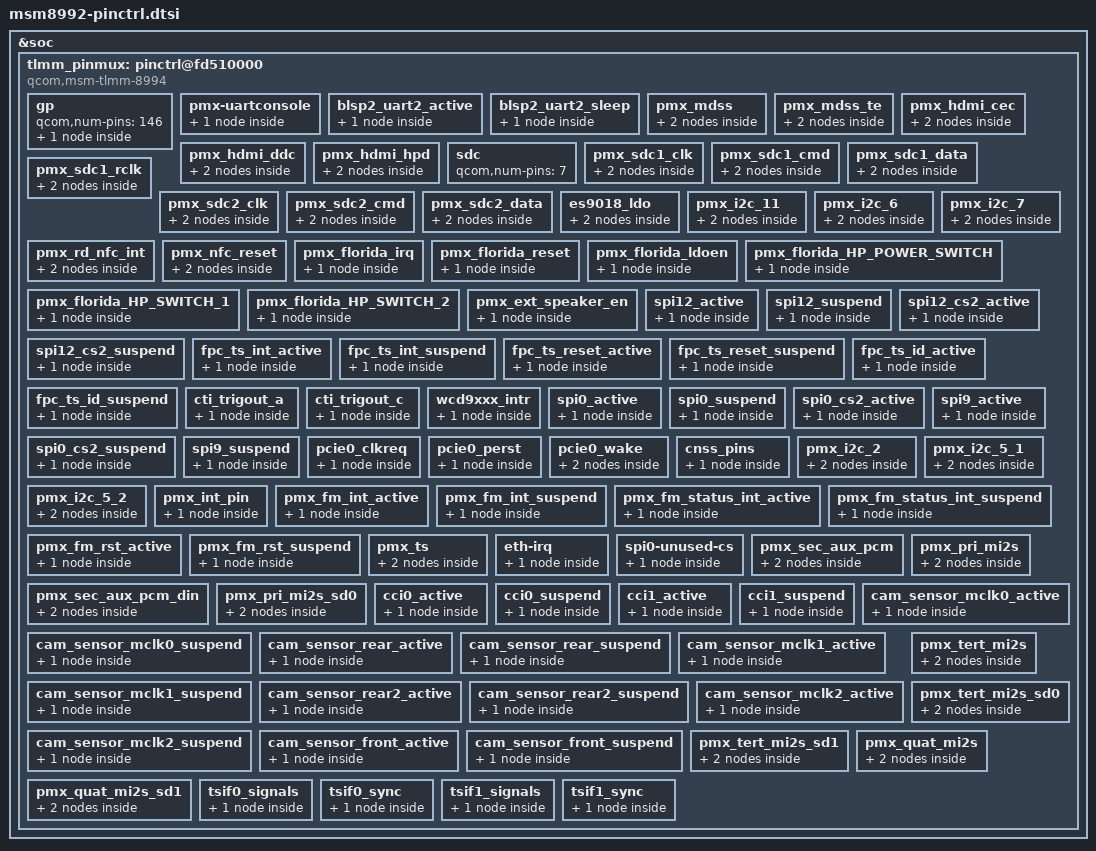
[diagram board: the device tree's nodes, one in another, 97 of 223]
/* Copyright (c) 2013-2015, The Linux Foundation. All rights reserved.
 *
 * This program is free software; you can redistribute it and/or modify
 * it under the terms of the GNU General Public License version 2 and
 * only version 2 as published by the Free Software Foundation.
 *
 * This program is distributed in the hope that it will be useful,
 * but WITHOUT ANY WARRANTY; without even the implied warranty of
 * MERCHANTABILITY or FITNESS FOR A PARTICULAR PURPOSE.  See the
 * GNU General Public License for more details.
 */

&soc {
	tlmm_pinmux: pinctrl@fd510000 {
		compatible = "qcom,msm-tlmm-8994", "qcom,msm-tlmm-8974";
		reg = <0xfd510000 0x4000>;
		interrupts = <0 208 0>;

		/*General purpose pins*/
		gp: gp {
			qcom,num-pins = <146>;
			#qcom,pin-cells = <1>;

			msm_gpio: msm_gpio {
				compatible = "qcom,msm-tlmm-gp";
				gpio-controller;
				#gpio-cells = <2>;
				interrupt-controller;
				#interrupt-cells = <2>;
				qcom,direct-connect-irqs = <8>;
				num_irqs = <146>;
			};
		};

		pmx-uartconsole {
			qcom,pins = <&gp 4>, <&gp 5>;
			qcom,num-grp-pins = <2>;
			qcom,pin-func = <2>;
			label = "uart-console";

		uart_console_sleep: uart-console {
				drive-strength = <2>;
				bias-pull-down;
			};
		};

		blsp2_uart2_active {
			qcom,pins = <&gp 45>, <&gp 46>, <&gp 47>, <&gp 48>;
			qcom,num-grp-pins = <4>;
			qcom,pin-func = <2>;
		        label = "blsp2_uart2_active";
			hsuart_active: default {
				drive-strength = <16>;
				bias-disable;
			};
		};

		blsp2_uart2_sleep {
			qcom,pins = <&gp 45>, <&gp 46>, <&gp 47>, <&gp 48>;
			qcom,num-grp-pins = <4>;
			qcom,pin-func = <0>;
		        label = "blsp2_uart2_sleep";
			hsuart_sleep: sleep {
				drive-strength = <2>;
				bias-disable;
			};
		};

		pmx_mdss: pmx_mdss {
			label = "mdss-pins";
			qcom,pin-func = <0>;
			mdss_dsi_active: active {
				drive-strength = <8>; /* 8 mA */
				bias-disable = <0>; /* no pull */
			};
			mdss_dsi_suspend: suspend {
				drive-strength = <2>; /* 2 mA */
				bias-pull-down; /* pull down */
			};
		};

		pmx_mdss_te: pmx_mdss_te {
			label = "mdss-te-pins";
			qcom,pin-func = <1>;
			mdss_te_active: active {
				drive-strength = <2>; /* 8 mA */
				bias-pull-down = <0>; /* pull down*/
				input-debounce = <0>;
			};
			mdss_te_suspend: suspend {
				drive-strength = <2>; /* 2 mA */
				bias-pull-down; /* pull down */
				input-debounce = <0>;
			};
		};

		pmx_hdmi_cec: pmx_hdmi_cec {
			qcom,pin-func = <1>;
			label = "hdmi-cec-pins";
			mdss_hdmi_cec_active: cec_active {
				drive-strength = <2>;
				bias-pull-up;
			};
			mdss_hdmi_cec_suspend: cec_suspend {
				drive-strength = <2>;
				bias-pull-down;
			};
		};

		pmx_hdmi_ddc: pmx_hdmi_ddc {
			qcom,pin-func = <1>;
			label = "hdmi-ddc-pins";
			mdss_hdmi_ddc_active: ddc_active {
				drive-strength = <2>;
				bias-pull-up;
			};
			mdss_hdmi_ddc_suspend: ddc_suspend {
				drive-strength = <2>;
				bias-pull-down;
			};
		};

		pmx_hdmi_hpd: pmx_hdmi_hpd {
			qcom,pin-func = <1>;
			label = "hdmi-hpd-pin";
			mdss_hdmi_hpd_active: hpd_active {
				drive-strength = <16>;
				bias-pull-down;
			};
			mdss_hdmi_hpd_suspend: hpd_suspend {
				drive-strength = <2>;
				bias-pull-down;
			};
		};
		/* SDC pin type */
		sdc: sdc {
			/* 0-3 for sdc1 4-6 for sdc2 */
			qcom,num-pins = <7>;
			/* Order of pins */
			/* SDC1: CLK -> 0, CMD -> 1, DATA -> 2, RCLK -> 3 */
			/* SDC2: CLK -> 4, CMD -> 5, DATA -> 6 */
			#qcom,pin-cells = <1>;
		};

		pmx_sdc1_clk {
			qcom,pins = <&sdc 0>;
			qcom,num-grp-pins = <1>;
			label = "sdc1-clk";
			sdc1_clk_on: clk_on {
				bias-disable; /* NO pull */
				drive-strength = <16>; /* 16 MA */
			};
			sdc1_clk_off: clk_off {
				bias-disable; /* NO pull */
				drive-strength = <2>; /* 2 MA */
			};
		};

		pmx_sdc1_cmd {
			qcom,pins = <&sdc 1>;
			qcom,num-grp-pins = <1>;
			label = "sdc1-cmd";
			sdc1_cmd_on: cmd_on {
				bias-pull-up; /* pull up */
				drive-strength = <8>; /* 8 MA */
			};
			sdc1_cmd_off: cmd_off {
				bias-pull-up = <0x3>; /* pull up */
				drive-strength = <2>; /* 2 MA */
			};
		};

		pmx_sdc1_data {
			qcom,pins = <&sdc 2>;
			qcom,num-grp-pins = <1>;
			label = "sdc1-data";
			sdc1_data_on: data_on {
				bias-pull-up; /* pull up */
				drive-strength = <8>; /* 8 MA */
			};
			sdc1_data_off: data_off {
				bias-pull-up; /* pull up */
				drive-strength = <2>; /* 2 MA */
			};
		};

		pmx_sdc1_rclk {
			qcom,pins = <&sdc 3>;
			qcom,num-grp-pins = <1>;
			label = "sdc1-rclk";
			sdc1_rclk_on: rclk_on {
				bias-pull-down; /* pull down */
			};
			sdc1_rclk_off: rclk_off {
				bias-pull-down; /* pull down */
			};
		};

		pmx_sdc2_clk {
			qcom,pins = <&sdc 4>;
			qcom,num-grp-pins = <1>;
			label = "sdc2-clk";
			sdc2_clk_on: clk_on {
				bias-disable; /* NO pull */
				drive-strength = <16>; /* 16 MA */
			};
			sdc2_clk_off: clk_off {
				bias-disable; /* NO pull */
				drive-strength = <2>; /* 2 MA */
			};
		};

		pmx_sdc2_cmd {
			qcom,pins = <&sdc 5>;
			qcom,num-grp-pins = <1>;
			label = "sdc2-cmd";
			sdc2_cmd_on: cmd_on {
				bias-pull-up; /* pull up */
				drive-strength = <10>; /* 10 MA */
			};
			sdc2_cmd_off: cmd_off {
				bias-pull-up; /* pull up */
				drive-strength = <2>; /* 2 MA */
			};
		};

		pmx_sdc2_data {
			qcom,pins = <&sdc 6>;
			qcom,num-grp-pins = <1>;
			label = "sdc2-data";
			sdc2_data_on: data_on {
				bias-pull-up; /* pull up */
				drive-strength = <10>; /* 10 MA */
			};
			sdc2_data_off: data_off {
				bias-pull-up; /* pull up */
				drive-strength = <2>; /* 2 MA */
			};
		};

		es9018_ldo {
			qcom,pins = <&gp 32>;
			qcom,num-grp-pins = <1>;
			qcom,pin-func = <0>;
			label = "es9018-ldo-en";
			es9018_ldo_act: lines_on {
						drive-strength = <8>;
						output-high;
						bias-pull-up;
					};
			es9018_ldo_sus: lines_off {
						drive-strength = <2>;
						output-low;
						bias-disable;
					};
		};
//add for lenovo upgrade M start
		pmx_i2c_11 {
			qcom,pins = <&gp 84>, <&gp 83>; /* SDA, SCL */
			qcom,num-grp-pins = <2>;
			qcom,pin-func = <3>;
			label = "pmx_i2c_11";

			i2c_11_active: i2c_11_active {
				  drive-strength = <8>;
				  bias-pull-up;
			  };

			i2c_11_sleep: i2c_11_sleep {
				 drive-strength = <2>;
				 bias-disable;
			 };
		};
//add for lenovo upgrade M end


		pmx_i2c_6 {
			qcom,pins = <&gp 28>, <&gp 27>; /* SDA, SCL */
			qcom,num-grp-pins = <2>;
			qcom,pin-func = <3>;
			label = "pmx_i2c_6";

			i2c_6_active: i2c_6_active {
				drive-strength = <2>;
				bias-disable;
			};

			i2c_6_sleep: i2c_6_sleep {
				drive-strength = <2>;
				bias-disable;
			};
		};
		pmx_i2c_7 {                                                                                                                                                                                                 
			qcom,pins = <&gp 44>, <&gp 43>; /* SDA, SCL */
			qcom,num-grp-pins = <2>;
			qcom,pin-func = <3>;
			label = "pmx_i2c_7";

			i2c_7_active: i2c_7_active {
				  drive-strength = <8>;
				  bias-pull-up;
			  };

			i2c_7_sleep: i2c_7_sleep {
				 drive-strength = <2>;
				 bias-disable;
			 };
		};


		pmx_rd_nfc_int{
			qcom,pins = <&gp 29>;
			qcom,pin-func = <0>;
			qcom,num-grp-pins = <1>;
			label = "pmx_nfc_int";

			nfc_int_active: active {
				drive-strength = <6>;
				bias-pull-up;
			};

			nfc_int_suspend: suspend {
				drive-strength = <6>;
				bias-pull-up;
			};
		};

		pmx_nfc_reset{
			qcom,pins = <&gp 30>;
			qcom,pin-func = <0>;
			qcom,num-grp-pins = <1>;
			label = "pmx_nfc_disable";

			nfc_disable_active: active {
				drive-strength = <6>;
				bias-pull-up;
			};

			nfc_disable_suspend: suspend {
				drive-strength = <6>;
				bias-disable;
			};
		};

		pmx_florida_irq {
		    qcom,pins = <&gp 41>;
		    qcom,num-grp-pins = <1>;
		    qcom,pin-func = <0>;
		    label = "florida_irq";
		    florida_irq_default: default {
			    bias-disable;
			    drive-strength = <2>;
		    };
	    };
	    
	    pmx_florida_reset {
		    qcom,pins = <&gp 14>;
		    qcom,num-grp-pins = <1>;
		    qcom,pin-func = <0>;
		    label = "florida_reset";
		    florida_reset_default: default {
			    output-high;
			    bias-pull-up;
			    drive-strength = <2>;
		    };
	    };

        pmx_florida_ldoen {
			qcom,pins = <&gp 16>;
			qcom,num-grp-pins = <1>;
			qcom,pin-func = <0>;
			label = "florida_ldoen";
			florida_ldoen_default: default {
			    output-low;
			    bias-disable;
			    drive-strength = <2>;
			};
		};

		pmx_florida_HP_POWER_SWITCH {
			qcom,pins = <&gp 31>;
			qcom,num-grp-pins = <1>;
			qcom,pin-func = <0>;
			label = "florida_hp_power_switch";
			florida_hp_power_default: default {
				output-high;
				bias-pull-up;
				drive-strength = <2>;
			};
		};

		pmx_florida_HP_SWITCH_1 {
			qcom,pins = <&gp 104>;
			qcom,num-grp-pins = <1>;
			qcom,pin-func = <0>;
			label = "florida_hp_switch_1";
			florida_hp_switch_1_default: default {
				output-high;
				bias-pull-up;
				drive-strength = <2>;
			};
		};

		pmx_florida_HP_SWITCH_2 {
			qcom,pins = <&gp 105>;
			qcom,num-grp-pins = <1>;
			qcom,pin-func = <0>;
			label = "florida_hp_switch_2";
			florida_hp_switch_2_default: default {
				output-high;
				bias-pull-up;
				drive-strength = <2>;
			};
		};

		pmx_ext_speaker_en {
			qcom,pins = <&gp 11>;
			qcom,num-grp-pins = <1>;
			qcom,pin-func = <0>;
			label = "ext_spk_pwr_en";
			ext_spk_pwr_en_default: default {
				output-low;
				bias-pull-up;
				drive-strength = <2>;
			};
		};

		 spi12_active {
			/* MOSI, MISO, CLK */
			qcom,pins = <&gp 85>, <&gp 86>, <&gp 88>;
			qcom,num-grp-pins = <3>;
			qcom,pin-func = <1>;
			label = " spi12-active";
			/* active state */
			 spi12_default: default {
				drive-strength = <12>; /* 12 MA */
				bias-disable = <0>; /* No PULL */
			};
		};

		 spi12_suspend {
			/* MOSI, MISO, CLK */
			qcom,pins = <&gp 85>, <&gp 86>, <&gp 88>;
			qcom,num-grp-pins = <3>;
			qcom,pin-func = <0>;
			label = " spi12-suspend";
			/* suspended state */
			 spi12_sleep: sleep {
				drive-strength = <2>; /* 2 MA */
				bias-pull-down; /* pull down */
			};
		};

		 spi12_cs2_active {
			/* CS */
			qcom,pins = <&gp 87>;
			qcom,num-grp-pins = <1>;
			qcom,pin-func = <1>;
			label = " spi12-cs2-active";
			 spi12_cs2_active: cs2_active {
				drive-strength = <2>;
				bias-disable = <0>;
			};
		};

		 spi12_cs2_suspend {
			/* CS */
			qcom,pins = <&gp 87>;
			qcom,num-grp-pins = <1>;
			qcom,pin-func = <0>;
			label = " spi12-cs2-suspend";
			 spi12_cs2_sleep: cs2_sleep {
				drive-strength = <2>;
				bias-disable = <0>;
			};
		};

		fpc_ts_int_active {
			qcom,pins = <&gp 90>;
			qcom,pin-func = <0>;
			qcom,num-grp-pins = <1>;
			label = "fpc_ts_int_active";

			fpc_int_active: fpc_int_active {
				drive-strength = <16>;
				bias-disable = <0>;
			};
		};
		fpc_ts_int_suspend {
			qcom,pins = <&gp 90>;
			qcom,pin-func = <0>;
			qcom,num-grp-pins = <1>;
			label = "fpc_ts_int_suspend";

			fpc_int_suspend: fpc_int_suspend {
				drive-strength = <2>;
				bias-disable = <0>;
			};
		};
		fpc_ts_reset_active {
			qcom,pins = <&gp 89>;
			qcom,pin-func = <0>;
			qcom,num-grp-pins = <1>;
			label = "fpc_ts_reset_active";

			fpc_reset_active: fpc_reset_active {
				drive-strength = <16>;
				bias-pull-up;
			};
		};
		fpc_ts_reset_suspend {
			qcom,pins = <&gp 89>;
			qcom,pin-func = <0>;
			qcom,num-grp-pins = <1>;
			label = "fpc_ts_reset_suspend";

			fpc_reset_suspend: fpc_reset_suspend {
				drive-strength = <2>;
				bias-disable = <0>;
			};
		};
		fpc_ts_id_active {
			qcom,pins = <&gp 62>;
			qcom,pin-func = <0>;
			qcom,num-grp-pins = <1>;
			label = "fpc_ts_id_active";

			fpc_id_active: fpc_id_active {
				drive-strength = <16>;
				bias-pull-down;
			};
		};
		fpc_ts_id_suspend {
			qcom,pins = <&gp 62>;
			qcom,pin-func = <0>;
			qcom,num-grp-pins = <1>;
			label = "fpc_ts_id_suspend";

			fpc_id_suspend: fpc_id_suspend {
				drive-strength = <2>;
				bias-disable = <0>;
			};
		};

		/* CoreSight */
		cti_trigout_a {
			qcom,pins = <&gp 91>;
			qcom,num-grp-pins = <1>;
			qcom,pin-func = <9>;
			label = "cti-trigout-a";
			trigout_a: trigout_a {
				drive-strength = <2>;
				bias-disable;
			};
		};

		cti_trigout_c {
			qcom,pins = <&gp 41>;
			qcom,num-grp-pins = <1>;
			qcom,pin-func = <4>;
			label = "cti-trigout-c";
			trigout_c: trigout_c {
				drive-strength = <2>;
				bias-disable;
			};
		};

		wcd9xxx_intr {
			qcom,pins = <&gp 72>;
			qcom,num-grp-pins = <1>;
			qcom,pin-func = <0>;
			label = "wcd-intr-default";
			wcd_intr_default: default {
				drive-strength = <2>; /* 2 MA */
				bias-pull-down; /* pull down */
				input-enable;
			};
		};

		spi0_active {
			/* MOSI, MISO, CLK */
			qcom,pins = <&gp 0>, <&gp 1>, <&gp 3>;
			qcom,num-grp-pins = <3>;
			qcom,pin-func = <1>;
			label = "spi0-active";
			/* active state */
			spi0_default: default {
				drive-strength = <12>; /* 12 MA */
				bias-disable = <0>; /* No PULL */
			};
		};

		spi0_suspend {
			/* MOSI, MISO, CLK */
			qcom,pins = <&gp 0>, <&gp 1>, <&gp 3>;
			qcom,num-grp-pins = <3>;
			qcom,pin-func = <0>;
			label = "spi0-suspend";
			/* suspended state */
			spi0_sleep: sleep {
				drive-strength = <2>; /* 2 MA */
				bias-pull-down; /* pull down */
			};
		};

		spi0_cs2_active {
			/* CS */
			qcom,pins = <&gp 2>;
			qcom,num-grp-pins = <1>;
			qcom,pin-func = <1>;
			label = "spi0-cs2-active";
			spi0_cs2_active: cs2_active {
				drive-strength = <2>;
				bias-disable = <0>;
			};
		};

		spi0_cs2_suspend {
			/* CS */
			qcom,pins = <&gp 2>;
			qcom,num-grp-pins = <1>;
			qcom,pin-func = <0>;
			label = "spi0-cs2-suspend";
			spi0_cs2_sleep: cs2_sleep {
				drive-strength = <2>;
				bias-disable = <0>;
			};
		};

		spi9_active {
			/* MOSI, MISO, CLK */
			qcom,pins = <&gp 53>, <&gp 54> ,<&gp 55> ,<&gp 56>;
			qcom,num-grp-pins = <4>;
			qcom,pin-func = <2>;
			label = "spi9-active";
			/* active state */
			spi9_default: default {
				drive-strength = <12>; /* 12 MA */
				bias-disable = <0>; /* No PULL */
			};
		};

		spi9_suspend {
			/* MOSI, MISO, CLK */
			qcom,pins = <&gp 53>, <&gp 54>, <&gp 55> ,<&gp 56>;
			qcom,num-grp-pins = <4>;
			qcom,pin-func = <2>;
			label = "spi9-suspend";
			/* suspended state */
			spi9_sleep: sleep {
				drive-strength = <2>; /* 2 MA */
				bias-pull-down; /* pull down */
			};
		};
	

		pcie0_clkreq {
			qcom,pins = <&gp 36>;
			qcom,num-grp-pins = <1>;
			qcom,pin-func = <2>;
			label = "pcie0-clkreq";
			/* default state */
			pcie0_clkreq_default: pcie0_clkreq_default {
				drive-strength = <2>;
				bias-pull-up;
			};
		};

		pcie0_perst {
			qcom,pins = <&gp 35>;
			qcom,num-grp-pins = <1>;
			label = "pcie0-perst";
			/* default state */
			pcie0_perst_default: pcie0_perst_default {
				drive-strength = <2>;
				bias-pull-down;
			};
		};

		pcie0_wake {
			qcom,pins = <&gp 37>;
			qcom,num-grp-pins = <1>;
			label = "pcie0-wake";
			/* default state */
			pcie0_wake_default: pcie0_wake_default {
				drive-strength = <2>;
				bias-pull-down;
			};

			pcie0_wake_sleep: pcie0_wake_sleep {
				drive-strength = <2>;
				bias-disable;
			};
		};

		cnss_pins {
			qcom,pins = <&gp 112>, <&gp 113>;
			qcom,num-grp-pins = <2>;
			qcom,pin-func = <0>;
			label = "cnss_pins";
			cnss_default: default {
				drive-strength = <16>;
				bias-pull-down;
			};
		};

		pmx_i2c_2 {
			qcom,pins = <&gp 6>, <&gp 7>; /* SDA, SCL */
			qcom,num-grp-pins = <2>;
			qcom,pin-func = <3>;
			label = "pmx_i2c_2";

			i2c_2_active: i2c_2_active {
				drive-strength = <2>;
				bias-disable;
			};

			i2c_2_sleep: i2c_2_sleep {
				drive-strength = <2>;
				bias-disable;
			};
		};

		pmx_i2c_5_1 {
			qcom,pins = <&gp 23>;
                        qcom,pin-func = <4>;
			qcom,num-grp-pins = <1>;
			label = "pmx_i2c_5_1";

			i2c_5_1_active: i2c_5_1_active {
				drive-strength = <2>;
				bias-disable;
			};

			i2c_5_1_sleep: i2c_5_1_sleep {
				drive-strength = <2>;
				bias-disable;
			};
		};


               pmx_i2c_5_2 {
                        qcom,pins = <&gp 24>;
                        qcom,pin-func = <5>;
                        qcom,num-grp-pins = <1>;
                        label = "pmx_i2c_5_2";

                        i2c_5_2_active: i2c_5_2_active {
                                drive-strength = <2>;
                                bias-disable;
                        };

                        i2c_5_2_sleep: i2c_5_2_sleep {
                                drive-strength = <2>;
                                bias-disable;
                        };
                };
/*
               pmx_i2c_5_int {
                         qcom,pins = <&gp 73>;
                         qcom,pin-func = <0>;
                         qcom,num-grp-pins = <1>;
                         label = "pmx_i2c_5_int";
                        i2c_5_int_active: active {
                                drive-strength = <6>;
                                bias-pull-up;
                        };

                        i2c_5_int_sleep: sleep {
                                drive-strength = <6>;
                                bias-pull-up;
                        };
              
               };
*/

               pmx_int_pin {
                        /* cwmcu sensor hub */
                        qcom,pins = <&gp 73>;
                        qcom,pin-func = <0>;
                        qcom,num-grp-pins = <1>;
                        label = "cwmcu-irq";
                        cwmcu_default: cwmcu_default {
                                drive-strength = <6>;
                                bias-pull-up;
                        };
                };


		pmx_fm_int_active {
			qcom,pins = <&gp 9>;
			qcom,pin-func = <0>;
			qcom,num-grp-pins = <1>;
			label = "pmx_fm_int_active";

			fm_int_active: fm_int_active {
				drive-strength = <16>;
				bias-pull-up;
			};
		};

		pmx_fm_int_suspend {
			qcom,pins = <&gp 9>;
			qcom,pin-func = <0>;
			qcom,num-grp-pins = <1>;
			label = "pmx_fm_int_suspend";

			fm_int_suspend: fm_int_suspend {
				drive-strength = <16>;
				bias-pull-up;
			};
		};

		pmx_fm_status_int_active {
			qcom,pins = <&gp 91>;
			qcom,pin-func = <0>;
			qcom,num-grp-pins = <1>;
			label = "pmx_fm_status_int_active";

			fm_status_int_active: fm_status_int_active {
				drive-strength = <16>;
				bias-pull-up;
			};
		};

		pmx_fm_status_int_suspend {
			qcom,pins = <&gp 91>;
			qcom,pin-func = <0>;
			qcom,num-grp-pins = <1>;
			label = "pmx_fm_status_int_suspend";

			fm_status_int_suspend: fm_status_int_suspend {
				drive-strength = <16>;
				bias-pull-up;
			};
		};

		pmx_fm_rst_active {
			qcom,pins = <&gp 62>;
			qcom,pin-func = <0>;
			qcom,num-grp-pins = <1>;
			label = "pmx_fm_rst_active";

			fm_rst_active: fm_rst_active {
				drive-strength = <16>;
				bias-pull-down;
			};
		};

		pmx_fm_rst_suspend {
			qcom,pins = <&gp 62>;
			qcom,pin-func = <0>;
			qcom,num-grp-pins = <1>;
			label = "pmx_fm_rst_suspend";

			fm_rst_suspend: fm_rst_suspend {
				drive-strength = <16>;
				bias-pull-down;
			};
		};

		pmx_ts {
			qcom,pins = <&gp 91>, <&gp 102>;
			qcom,pin-func = <0>;
			qcom,num-grp-pins = <2>;
			label = "pmx_ts";

			ts_active: ts_active {
				drive-strength = <16>;
				bias-pull-up;
			};

			ts_suspend: ts_suspend {
				drive-strength = <16>;
				bias-disable;
			};
		};

		eth-irq {
			qcom,pins = <&gp 91>;
			qcom,num-grp-pins = <1>;
			qcom,pin-func = <0>;
			label = "eth-irq";
			eth_irq_default: default {
				drive-strength = <2>;
				bias-pull-up;
			};
		};

		spi0-unused-cs {
			qcom,pins = <&gp 8>, <&gp 10>, <&gp 91>;
			qcom,num-grp-pins = <3>;
			qcom,pin-func = <0>;
			label = "unused-cs";
			spi0_unused_cs_default: default {
				drive-strength = <2>;
				bias-pull-up;
			};
		};


		pmx_sec_aux_pcm {
			qcom,pins = <&gp 79>, <&gp 80>, <&gp 82>;
			qcom,num-grp-pins = <3>;
			qcom,pin-func = <1>;
			label = "sec_aux_pcm";
			sec_aux_pcm_sleep: sec_aux_pcm_sleep {
				drive-strength = <2>;	/* 2 mA */
				bias-pull-down;		/* PULL DOWN */
			};
			sec_aux_pcm_active: sec_aux_pcm_active {
				drive-strength = <8>;	/* 8 mA */
				bias-disable;		/* NO PULL */
				output-high;
			};
		};

		pmx_sec_aux_pcm_din {
			qcom,pins = <&gp 81>;
			qcom,num-grp-pins = <1>;
			qcom,pin-func = <1>;
			label = "sec_aux_pcm_din";
			sec_aux_pcm_din_sleep: sec_aux_pcm_din_sleep {
				drive-strength = <2>;	/* 2 mA */
				bias-pull-down;		/* PULL DOWN */
			};
			sec_aux_pcm_din_active: sec_aux_pcm_din_active {
				drive-strength = <8>;	/* 8 mA */
				bias-disable;		/* NO PULL */
			};
		};

		pmx_pri_mi2s {
			qcom,pins = <&gp 65>, <&gp 66>;
			qcom,num-grp-pins = <2>;
			qcom,pin-func = <1>;
			label = "pri_mi2s";
			pri_mi2s_sleep: pri_mi2s_sleep {
				drive-strength = <2>;	/* 2 mA */
				bias-pull-down;		/* PULL DOWN */
			};
			pri_mi2s_active: pri_mi2s_active {
				drive-strength = <2>;	/* 2 mA */
				bias-disable;		/* NO PULL */
				output-high;
			};
		};

		pmx_pri_mi2s_sd0 {
			qcom,pins = <&gp 67>, <&gp 68>;
			qcom,num-grp-pins = <2>;
			qcom,pin-func = <1>;
			label = "pri_mi2s_sd0";
			pri_mi2s_sd0_sleep: pri_mi2s_sd0_sleep {
				drive-strength = <2>;	/* 2 mA */
				bias-pull-down;		/* PULL DOWN */
			};
			pri_mi2s_sd0_active: pri_mi2s_sd0_active {
				drive-strength = <2>;	/* 2 mA */
				bias-disable;		/* NO PULL */
			};
		};


		/* pin-ctrl for camera sensor */
		cci0_active {
			/* CLK, DATA */
			qcom,pins = <&gp 17>, <&gp 18>;
			qcom,num-grp-pins = <2>;
			qcom,pin-func = <1>;
			label = "cci0-active";
			/* active state */
			cci0_active: cci0_active {
				drive-strength = <2>; /* 2 MA */
				bias-disable; /* No PULL */
			};
		};

		cci0_suspend {
			/* CLK, DATA */
			qcom,pins = <&gp 17>, <&gp 18>;
			qcom,num-grp-pins = <2>;
			qcom,pin-func = <0>;
			label = "cci0-suspend";
			/*suspended state */
			cci0_suspend: cci0_suspend {
				drive-strength = <2>; /* 2 MA */
				bias-disable; /* No PULL */
			};
		};

		cci1_active {
			/* CLK, DATA */
			qcom,pins = <&gp 19>, <&gp 20>;
			qcom,num-grp-pins = <2>;
			qcom,pin-func = <1>;
			label = "cci1-active";
			/* active state */
			cci1_active: cci1_active {
				drive-strength = <2>; /* 2 MA */
				bias-disable; /* No PULL */
			};
		};

		cci1_suspend {
			/* CLK, DATA */
			qcom,pins = <&gp 19>, <&gp 20>;
			qcom,num-grp-pins = <2>;
			qcom,pin-func = <0>;
			label = "cci1-suspend";
			/*suspended state */
			cci1_suspend: cci1_suspend {
				drive-strength = <2>; /* 2 MA */
				bias-disable; /* No PULL */
			};
		};

		cam_sensor_mclk0_active {
			/* MCLK0 */
			qcom,pins = <&gp 13>;
			qcom,num-grp-pins = <1>;
			qcom,pin-func = <1>;
			label = "cam_sensor_mclk0_active";
			/* active state */
			cam_sensor_mclk0_active: cam_sensor_mclk0_active {
				drive-strength = <2>; /* 2 MA */
				bias-disable; /* No PULL */
			};
		};

		cam_sensor_mclk0_suspend {
			/* MCLK0 */
			qcom,pins = <&gp 13>;
			qcom,num-grp-pins = <1>;
			label = "cam_sensor_mclk0_suspend";
			/*suspended state */
			cam_sensor_mclk0_suspend: cam_sensor_mclk0_suspend {
				drive-strength = <2>; /* 2 MA */
				bias-pull-down; /* PULL DOWN */
			};
		};

		cam_sensor_rear_active {
			/* RESET, STANDBY */
			qcom,pins = <&gp 92>;
			qcom,num-grp-pins = <1>;
			label = "cam_sensor_rear_active";
			/* active state */
			cam_sensor_rear_active: cam_sensor_rear_active {
				drive-strength = <2>; /* 2 MA */
				bias-disable; /* No PULL */
			};
		};

		cam_sensor_rear_suspend {
			/* RESET, STANDBY */
			qcom,pins = <&gp 92>;
			qcom,num-grp-pins = <1>;
			label = "cam_sensor_rear_suspend";
			/*suspended state */
			cam_sensor_rear_suspend: cam_sensor_rear_suspend {
				drive-strength = <2>; /* 2 MA */
				bias-disable; /* No PULL */
			};
		};

		cam_sensor_mclk1_active {
			/* MCLK2 */
			qcom,pins = <&gp 91>;
			qcom,num-grp-pins = <1>;
			qcom,pin-func = <1>;
			label = "cam_sensor_mclk1_active";
			/* active state */
			cam_sensor_mclk1_active: cam_sensor_mclk1_active {
				drive-strength = <2>; /* 2 MA */
				bias-disable; /* No PULL */
			};
		};

		cam_sensor_mclk1_suspend {
			/* MCLK2 */
			qcom,pins = <&gp 91>;
			qcom,num-grp-pins = <1>;
			label = "cam_sensor_mclk1_suspend";
			/* suspend state */
			cam_sensor_mclk1_suspend: cam_sensor_mclk1_suspend {
				drive-strength = <2>; /* 2 MA */
				bias-pull-down; /* PULL DOWN */
			};
		};

		cam_sensor_rear2_active {
			/* RESET, STANDBY */
//			qcom,pins = <&gp 94>, <&gp 93>;
			qcom,num-grp-pins = <0>;
			label = "cam_sensor_rear2_active";
			/* active state */
			cam_sensor_rear2_active: cam_sensor_rear2_active {
				drive-strength = <2>; /* 2 MA */
				bias-disable; /* No PULL */
			};
		};

		cam_sensor_rear2_suspend {
			/* RESET, STANDBY */
//			qcom,pins = <&gp 94>, <&gp 93>;
			qcom,num-grp-pins = <0>;
			label = "cam_sensor_rear2_suspend";
			/*suspended state */
			cam_sensor_rear2_suspend: cam_sensor_rear2_suspend {
				drive-strength = <2>; /* 2 MA */
				bias-disable; /* No PULL */
			};
		};

		cam_sensor_mclk2_active {
			/* MCLK2 */
			qcom,pins = <&gp 15>;
			qcom,num-grp-pins = <1>;
			qcom,pin-func = <1>;
			label = "cam_sensor_mclk2_active";
			/* active state */
			cam_sensor_mclk2_active: cam_sensor_mclk2_active {
				drive-strength = <2>; /* 2 MA */
				bias-disable; /* No PULL */
			};
		};

		cam_sensor_mclk2_suspend {
			/* MCLK2 */
			qcom,pins = <&gp 15>;
			qcom,num-grp-pins = <1>;
			label = "cam_sensor_mclk2_suspend";
			/* suspend state */
			cam_sensor_mclk2_suspend: cam_sensor_mclk2_suspend {
				drive-strength = <2>; /* 2 MA */
				bias-pull-down; /* PULL DOWN */
			};
		};

		cam_sensor_front_active {
			/* RESET, VIO */
			qcom,pins = <&gp 94>, <&gp 93>;
			qcom,num-grp-pins = <2>;
			label = "cam_sensor_front_active";
			/* active state */
			cam_sensor_front_active: cam_sensor_front_active {
				drive-strength = <2>; /* 2 MA */
				bias-disable; /* No PULL */
			};
		};

		cam_sensor_front_suspend {
			/* RESET, VIO */
			qcom,pins = <&gp 94>, <&gp 93>;
			qcom,num-grp-pins = <2>;
			label = "cam_sensor_front_suspend";
			/*suspended state */
			cam_sensor_front_suspend: cam_sensor_front_suspend {
				drive-strength = <2>; /* 2 MA */
				bias-disable; /* No PULL */
			};
		};

        pmx_tert_mi2s {
			qcom,pins = <&gp 74>, <&gp 75>;
			qcom,num-grp-pins = <2>;
			qcom,pin-func = <1>;
			label = "tert_mi2s";
			tert_mi2s_sleep: tert_mi2s_sleep {
				drive-strength = <2>;	/* 2 mA */
				bias-pull-down;		/* PULL DOWN */
			};
			tert_mi2s_active: tert_mi2s_active {
				drive-strength = <8>;	/* 8 mA */
				bias-disable;		/* NO PULL */
				output-high;
			};
		};

		pmx_tert_mi2s_sd0 {
			qcom,pins = <&gp 76>;
			qcom,num-grp-pins = <1>;
			qcom,pin-func = <1>;
			label = "tert_mi2s_sd0";
			tert_mi2s_sd0_sleep: tert_mi2s_sd0_sleep {
				drive-strength = <2>;	/* 2 mA */
				bias-pull-down;		/* PULL DOWN */
			};
			tert_mi2s_sd0_active: tert_mi2s_sd0_active {
				drive-strength = <8>;	/* 8 mA */
				bias-disable;		/* NO PULL */
			};
		};

		pmx_tert_mi2s_sd1 {
			qcom,pins = <&gp 77>;
			qcom,num-grp-pins = <1>;
			qcom,pin-func = <1>;
			label = "tert_mi2s_sd1";
			tert_mi2s_sd1_sleep: tert_mi2s_sd1_sleep {
				drive-strength = <2>;	/* 2 mA */
				bias-pull-down;		/* PULL DOWN */
			};
			tert_mi2s_sd1_active: tert_mi2s_sd1_active {
				drive-strength = <8>;	/* 8 mA */
				bias-disable;		/* NO PULL */
			};
		};

		pmx_quat_mi2s {
			qcom,pins = <&gp 58>, <&gp 59>;
			qcom,num-grp-pins = <2>;
			qcom,pin-func = <1>;
			label = "quat_mi2s";
			quat_mi2s_sleep: quat_mi2s_sleep {
				drive-strength = <2>;	/* 2 mA */
				bias-pull-down;		/* PULL DOWN */
			};
			quat_mi2s_active: quat_mi2s_active {
				drive-strength = <8>;	/* 8 mA */
				bias-disable;		/* NO PULL */
				output-high;
			};
		};


		pmx_quat_mi2s_sd1 {
			qcom,pins = <&gp 61>;
			qcom,num-grp-pins = <1>;
			qcom,pin-func = <1>;
			label = "quat_mi2s_sd1";
			quat_mi2s_sd1_sleep: quat_mi2s_sd1_sleep {
				drive-strength = <2>;	/* 2 mA */
				bias-pull-down;		/* PULL DOWN */
			};
			quat_mi2s_sd1_active: quat_mi2s_sd1_active {
				drive-strength = <8>;	/* 8 mA */
				bias-disable;		/* NO PULL */
			};
		};
		tsif0_signals {
			qcom,pins = <&gp 89>,	/* TSIF0 CLK */
				<&gp 90>,	/* TSIF0 Enable */
				<&gp 91>;	/* TSIF0 DATA */
			qcom,num-grp-pins = <3>;
			qcom,pin-func = <1>;
			label = "tsif0-signals";
			tsif0_signals_active: tsif0_signals_active {
				drive_strength = <2>;	/* 2 mA */
				bias-pull-down;		/* pull down */
			};
		};

		/* sync signal is only used if configured to mode-2 */
		tsif0_sync {
			qcom,pins = <&gp 110>;	/* TSIF0 SYNC */
			qcom,num-grp-pins = <1>;
			qcom,pin-func = <1>;
			label = "tsif0-sync";
			tsif0_sync_active: tsif0_sync_active {
				drive_strength = <2>;	/* 2 mA */
				bias-pull-down;		/* pull down */
			};
		};

		tsif1_signals {
			qcom,pins = <&gp 93>,	/* TSIF1 CLK */
				<&gp 94>,	/* TSIF1 Enable */
				<&gp 95>;	/* TSIF1 DATA */
			qcom,num-grp-pins = <3>;
			qcom,pin-func = <1>;
			label = "tsif1-signals";
			tsif1_signals_active: tsif1_signals_active {
				drive_strength = <2>;	/* 2 mA */
				bias-pull-down;		/* pull down */
			};
		};

		/* sync signal is only used if configured to mode-2 */
		tsif1_sync {
			qcom,pins = <&gp 96>;	/* TSIF1 SYNC */
			qcom,num-grp-pins = <1>;
			qcom,pin-func = <1>;
			label = "tsif1-sync";
			tsif1_sync_active: tsif1_sync_active {
				drive_strength = <2>;	/* 2 mA */
				bias-pull-down;		/* pull down */
			};
		};
	};
};
